# wl_phy_common_secure register map
Vendor: Texas Instruments
Peripheral module from a debugger description file (folder CC35X1E).
Registers are 32-bit, access per field, reset 0x0 unless marked. A register's access mark holds for its fields unless they carry their own. Offsets are as the file gives them; lines under a group give offsets from that group; [hi:lo] are bit positions; {n}, {i} and the like mark numbered series; 'fields as' and 'values as' point back to an identical list; <NAME> marks a mode.

## wl_phy_common_secure
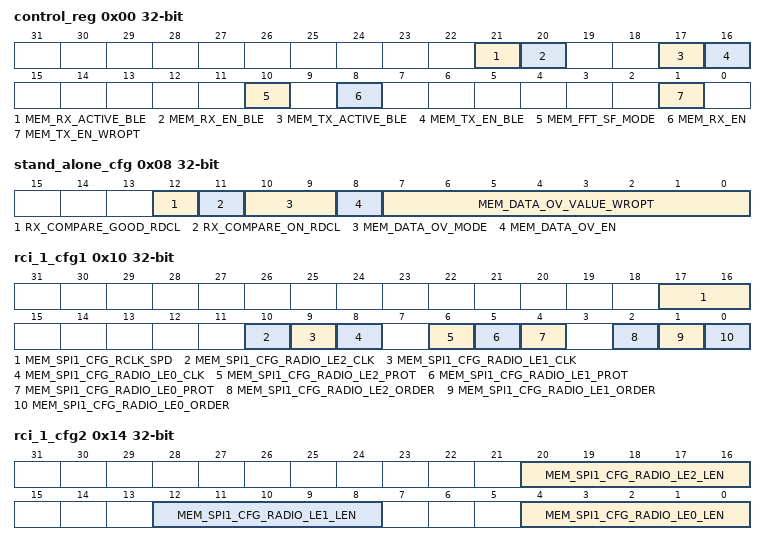
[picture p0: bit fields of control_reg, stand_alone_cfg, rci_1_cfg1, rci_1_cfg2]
0x00 control_reg reset not defined
  [21] MEM_RX_ACTIVE_BLE rw
  [20] MEM_RX_EN_BLE rw
  [17] MEM_TX_ACTIVE_BLE rw
  [16] MEM_TX_EN_BLE rw
  [10] MEM_FFT_SF_MODE rw
  [8] MEM_RX_EN rw — Rx En control 1 - En Rx 0 - Disable Rx
  [1] MEM_TX_EN_WROPT rw — Tx En control for clock Gating. Set by H/W upon MAC Header rise is detected by Tx Control module. Set by S/W to set tx clock and usually together with MEM_TX_START_WRCL. 1 - En Tx 0 - Disable Tx
0x04 fpga_ctrl reset not defined
  [13:0] MEM_FPGA_FC_INV rw
0x08 stand_alone_cfg
  [12] RX_COMPARE_GOOD_RDCL ro
  [11] RX_COMPARE_ON_RDCL ro
  [10:9] MEM_DATA_OV_MODE rw — 0 - Constant mode ('mem_data_ov_value' is transmitted) 1 - Increament mode ('mem_data_ov_value' is transmitted and increamented per tx_data_rd / rx_data_en) 2 - Memory mode ('mem_data_ov_3fc_wrmem' is transmitted one byte at a time starting from address 0)
  [8] MEM_DATA_OV_EN rw — 0 - Normal mode 1 - PHY srand alone mode - use data according to 'MEM_DATA_OV_MODE' instead of TX_DATA from MAC
  [7:0] MEM_DATA_OV_VALUE_WROPT rw — Use in Stand alone mode as: Tx - the TX_DATA Rx - the Compare date (when mem_data_ov_en=1)
0x0C fpga_spare1 rw
  [31:0] MEM_FPGA_SPARE1
0x10 rci_1_cfg1 reset not defined — Radio Serial Interface Configuration (RCI_CFG1)
  [17:16] MEM_SPI1_CFG_RCLK_SPD rw — Selects between 3 RCLK speeds depending on MAC clock frequency: 40/80 MHz MAC clock _ 0 = 6.67/13.33 MHz. 1 = 3.33/6.67 MHz. 2 or 3 = 1.67/3.33 MHz.
  [10] MEM_SPI1_CFG_RADIO_LE2_CLK rw — 1 - add an extra clock for the latch enable (to support the Nokia radio serial interface) for radio_le2.
  [9] MEM_SPI1_CFG_RADIO_LE1_CLK rw — 1 - add an extra clock for the latch enable (to support the Nokia radio serial interface) for radio_le1.
  [8] MEM_SPI1_CFG_RADIO_LE0_CLK rw — 1 - add an extra clock for the latch enable (to support the Nokia radio serial interface) for radio_le0.
  [6] MEM_SPI1_CFG_RADIO_LE2_PROT rw — Protocol for radio_le2 (0 = strobe. 1 = low active)
  [5] MEM_SPI1_CFG_RADIO_LE1_PROT rw — Protocol for radio_le1 (0 = strobe. 1 = low active) (Philips CS-SYNTH)
  [4] MEM_SPI1_CFG_RADIO_LE0_PROT rw — Protocol for radio_le0 (0 = strobe. 1 = low active) (Philips CS-1630)
  [2] MEM_SPI1_CFG_RADIO_LE2_ORDER rw — Bit order for radio_le2 (0 = lsb to msb. 1 = msb to lsb)
  [1] MEM_SPI1_CFG_RADIO_LE1_ORDER rw — Bit order for radio_le1 (0 = lsb to msb. 1 = msb to lsb) (Philips CS-SYNTH)
  [0] MEM_SPI1_CFG_RADIO_LE0_ORDER rw — Bit order for radio_le0 (0 = lsb to msb. 1 = msb to lsb) (Philips CS-1630)
0x14 rci_1_cfg2 reset not defined — Radio Serial Interface Register Length (RCI_CFG2)
  [20:16] MEM_SPI1_CFG_RADIO_LE2_LEN rw — The bit width of the internal radio registers for radio_le2
  [12:8] MEM_SPI1_CFG_RADIO_LE1_LEN rw — The bit width of the internal radio registers for radio_le1. (Philips CS-SYNTH)
  [4:0] MEM_SPI1_CFG_RADIO_LE0_LEN rw — The bit width of the internal radio registers for radio_le0. (Philips CS-1630)
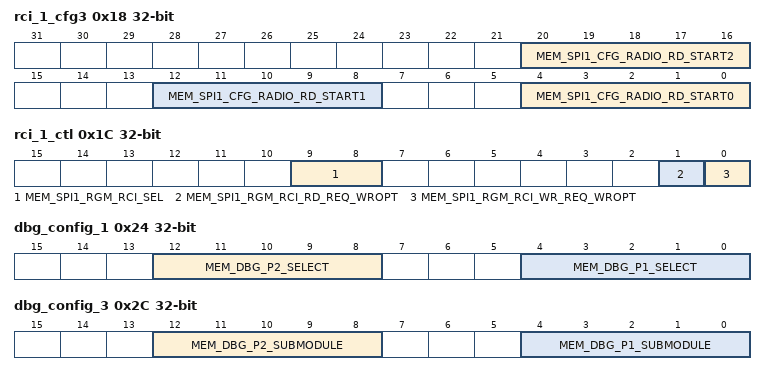
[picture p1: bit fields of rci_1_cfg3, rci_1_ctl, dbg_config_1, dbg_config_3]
0x18 rci_1_cfg3 — Radio Serial Interface Register Address Length (RCI_CFG3)
  [20:16] MEM_SPI1_CFG_RADIO_RD_START2 rw — For a register read, the number of bits to initially write, before reading the remaining bits for radio_le2.
  [12:8] MEM_SPI1_CFG_RADIO_RD_START1 rw — For a register read, the number of bits to initially write, before reading the remaining bits for radio_le1.
  [4:0] MEM_SPI1_CFG_RADIO_RD_START0 rw — For a register read, the number of bits to initially write, before reading the remaining bits for radio_le0.
0x1C rci_1_ctl — Radio Register Request (RCI_CTL)
  [9:8] MEM_SPI1_RGM_RCI_SEL rw — Select between latch enable 2. 1 or 0
  [1] MEM_SPI1_RGM_RCI_RD_REQ_WROPT rw — Read request. Cleared upon receiving ack strobe.
  [0] MEM_SPI1_RGM_RCI_WR_REQ_WROPT rw — Write request. Cleared upon receiving ack strobe.
0x20 rci_1_data rw — Radio Register Data (RCI_DATA)
  [31:0] MEM_SPI1_RGM_RCI_DATA_WROPT — Write data to radio registers
0x24 dbg_config_1
  [12:8] MEM_DBG_P2_SELECT rw, [4:0] MEM_DBG_P1_SELECT rw
0x2C dbg_config_3
  [12:8] MEM_DBG_P2_SUBMODULE rw, [4:0] MEM_DBG_P1_SUBMODULE rw
0x30 control_reg_2 reset not defined
  [0] MEM_TX_START_WRCL wo — Tx Start control When set to '1' will invoke Tx packet This field is self Clear (Clear on Write)
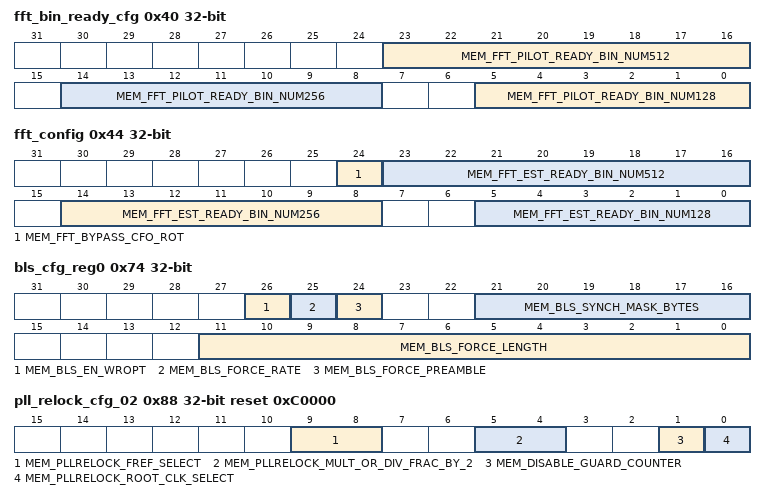
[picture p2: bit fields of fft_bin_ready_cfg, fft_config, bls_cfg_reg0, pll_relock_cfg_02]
0x40 fft_bin_ready_cfg reset not defined
  [23:16] MEM_FFT_PILOT_READY_BIN_NUM512 rw, [14:8] MEM_FFT_PILOT_READY_BIN_NUM256 rw, [5:0] MEM_FFT_PILOT_READY_BIN_NUM128 rw
0x44 fft_config reset not defined
  [24] MEM_FFT_BYPASS_CFO_ROT rw, [23:16] MEM_FFT_EST_READY_BIN_NUM512 rw, [14:8] MEM_FFT_EST_READY_BIN_NUM256 rw, [5:0] MEM_FFT_EST_READY_BIN_NUM128 rw
0x48 packet_cnt_bd_11b rw
  [31:0] MEM_PACKET_CNT_BD_11B_WROPT
0x4C packet_cnt_bd_ofdm rw
  [31:0] MEM_PACKET_CNT_BD_OFDM_WROPT
0x50 packet_cnt_rx_hdr rw
  [31:0] MEM_PACKET_CNT_RX_HDR_WROPT
0x54 packet_cnt_good_data rw
  [31:0] MEM_PACKET_CNT_GOOD_DATA_WROPT
0x58 packet_cnt_ls_reject rw
  [31:0] MEM_PACKET_CNT_LS_REJECT_WROPT
0x5C packet_cnt_stomp rw
  [31:0] MEM_PACKET_CNT_STOMP_WROPT
0x60 packet_cnt_rx_hdr_err rw
  [31:0] MEM_PACKET_CNT_RX_HDR_ERR_WROPT
0x64 packet_cnt_pd_dismissed rw
  [31:0] MEM_PACKET_CNT_PD_DISMISSED_WROPT
0x68 rf_balcony_sel_sw_reg ro
  [6:0] RF_BALCONY_SEL_SW — Read the Dip switch value Bit 0 -> SW8 (most right , near the Jtag Connector) Bit 5 -> SW2 (left side)
0x6C packet_cnt_tx_hdr rw
  [31:0] MEM_PACKET_CNT_TX_HDR_WROPT
0x70 packet_cnt_rx_unsupported rw
  [31:0] MEM_PACKET_CNT_RX_UNSUPPORTED_WROPT
0x74 bls_cfg_reg0 reset not defined
  [26] MEM_BLS_EN_WROPT rw — 0: Normal mode 1: BLS mode
  [25] MEM_BLS_FORCE_RATE rw — 0: 1DSSS 1: 2DSSS
  [24] MEM_BLS_FORCE_PREAMBLE rw — 0: Short Preamble 1: Long Preamble
  [21:16] MEM_BLS_SYNCH_MASK_BYTES rw — Mask the non-relevant bytes in the sequence
  [11:0] MEM_BLS_FORCE_LENGTH rw — The number of bytes to receive after sync
0x78 bls_cfg_reg1 rw
  [31:0] MEM_BLS_SYNCH_PATTERN_LSB — Synchronization pattern for BLS LSB bits [31:0]
0x7C bls_cfg_reg2
  [15:0] MEM_BLS_SYNCH_PATTERN_MSB rw — Synchronization pattern for BLS MSB bits [47:32]
0x80 pll_relock_cfg_00 — PLL Relock Configuration register
  [26:0] MEM_PLLRELOCK_CHANNEL_FREQ_MHZ rw — For Tx resampler ratio calculation <13.14u>
0x84 pll_relock_cfg_01 — PLL Relock Configuration register
  [0] MEM_PLLRELOCK_FW_TRIG_FOR_TXRESAMP_WRCL wo — Write clear - Using the divider of the Tx Resampler Ratio as HW accelerator for the FW
0x88 pll_relock_cfg_02 reset 0xC0000 (reset mask 0xFFFFFC00) — PLL Relock Configuration register
  [9:8] MEM_PLLRELOCK_FREF_SELECT rw — Selection of PLL reference clock: 0 - 80MHz 1 - 78MHz 2 - 104MHz 3 - 96MHz REF_CLK=(XTAL_CLK * DLL)/R
  [5:4] MEM_PLLRELOCK_MULT_OR_DIV_FRAC_BY_2 rw — Need to multiply or div by 2. 0 - mult by 1 1 - mult by 2 2 - div by 2 For 2.4GHz band = 0 or 1 For 5GHz band = 0 or 2
  [1] MEM_DISABLE_GUARD_COUNTER rw — This disable the guard of 7 clocks between calc done to going to IDLE. the reason is that we need to guarntee that two consecutive kicks are not asserted too fast. this could happen if trigger indication rise and then falls quickly. this counter make sure the kicks are spaced
  [0] MEM_PLLRELOCK_ROOT_CLK_SELECT rw — Selection of band == root clock: 0 - 2.4GHz band = 4/3 1 - 5GHz band = 4/7
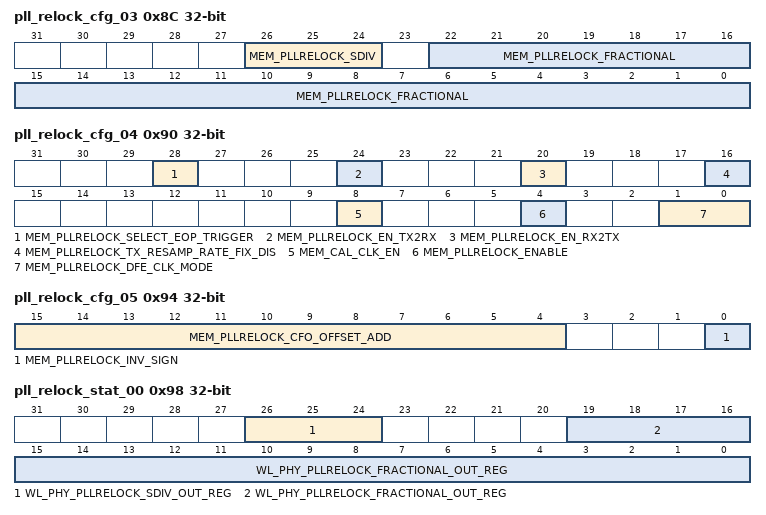
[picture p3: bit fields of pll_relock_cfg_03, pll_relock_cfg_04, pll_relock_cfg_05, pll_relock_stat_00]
0x8C pll_relock_cfg_03 — PLL Relock Configuration register
  [26:24] MEM_PLLRELOCK_SDIV rw — Original PLL sdiv word - will be written by PHY FW at tune
  [22:0] MEM_PLLRELOCK_FRACTIONAL rw — Fractional word - will be written by PHY FW at tune
0x90 pll_relock_cfg_04 reset not defined — PLL Relock Configuration register
  [28] MEM_PLLRELOCK_SELECT_EOP_TRIGGER rw — Select whether TdEop or TdDataEop triggers the PLL change 0 - TdEop 1 - TdDataEop
  [24] MEM_PLLRELOCK_EN_TX2RX rw — Enables actual PLL FCW change and Tx re-sampler update after the Tx of TB MU
  [20] MEM_PLLRELOCK_EN_RX2TX rw — Enables actual PLL FCW change and Tx re-sampler update once finish calculations, before Tx
  [16] MEM_PLLRELOCK_TX_RESAMP_RATE_FIX_DIS rw — Clibration clock enable
  [8] MEM_CAL_CLK_EN rw — Clibration clock enable
  [4] MEM_PLLRELOCK_ENABLE rw — Module Enabler
  [1:0] MEM_PLLRELOCK_DFE_CLK_MODE rw — Selection of Tx DFE clock mode, affects "Fin_div_Fout_ofdm_New" calculation 0 - BG (RCD32) 1 - A (CKVD48) 2 - E (CKVD64) 3 - BLE (RCD30)
0x94 pll_relock_cfg_05 — PLL Relock Configuration register
  [15:4] MEM_PLLRELOCK_CFO_OFFSET_ADD rw — An option to add external offset (i.e. temperature offset)
  [0] MEM_PLLRELOCK_INV_SIGN rw — In case Phase tracking output is inverted (Phase tracking output has similar configuration)
0x98 pll_relock_stat_00 ro — PLL Relock Status register
  [26:24] WL_PHY_PLLRELOCK_SDIV_OUT_REG — PLL sdiv calculated word - Status register to be used by FW as risk mitigation
  [19:0] WL_PHY_PLLRELOCK_FRACTIONAL_OUT_REG — PLL fractional calculated word - Status register to be used by FW as risk mitigation
0x9C pll_relock_stat_01 ro — PLL Relock Status register
  [25:0] WL_PHY_PLLRELOCK_TX_RESAMPLER_RATIO_OUT_REG — Tx re-sampler calculated word - Status register to be used by FW as risk mitigation
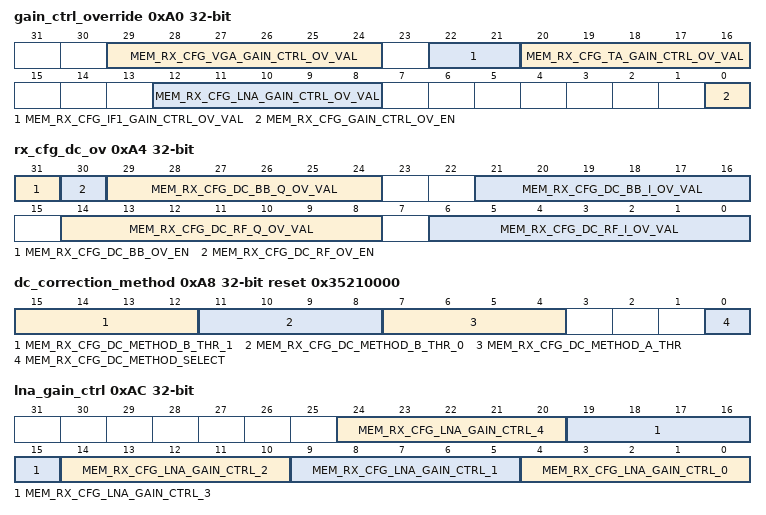
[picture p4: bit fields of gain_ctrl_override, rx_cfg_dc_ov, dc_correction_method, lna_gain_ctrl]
0xA0 gain_ctrl_override — RX CFG Gain Control Override configuration register
  [29:24] MEM_RX_CFG_VGA_GAIN_CTRL_OV_VAL rw — VGA override value (same for I&Q) <5.0>
  [22:21] MEM_RX_CFG_IF1_GAIN_CTRL_OV_VAL rw — IF1 override value (same for I&Q) <1.0>
  [20:16] MEM_RX_CFG_TA_GAIN_CTRL_OV_VAL rw — TA override value (same for I&Q) <4.0>
  [12:8] MEM_RX_CFG_LNA_GAIN_CTRL_OV_VAL rw — LNA override value <5.0>
  [0] MEM_RX_CFG_GAIN_CTRL_OV_EN rw — Override-enable. When this bit is set to '1', the amplifiers control will be according to OV_VAL registers
0xA4 rx_cfg_dc_ov — RX CFG DC Correction Override configuration register
  [31] MEM_RX_CFG_DC_BB_OV_EN rw — DC BB correction DAC override-enable. When this bit is set to '1', the DC BB DACs will get the OV_VAL
  [30] MEM_RX_CFG_DC_RF_OV_EN rw — DC RF correction DAC override-enable. When this bit is set to '1', the DC RF DACs will get the OV_VAL
  [29:24] MEM_RX_CFG_DC_BB_Q_OV_VAL rw — DC BB DAC Q correction word <5.0>
  [21:16] MEM_RX_CFG_DC_BB_I_OV_VAL rw — DC BB DAC I correction word <5.0>
  [14:8] MEM_RX_CFG_DC_RF_Q_OV_VAL rw — DC RF DAC Q correction word <8.0>
  [6:0] MEM_RX_CFG_DC_RF_I_OV_VAL rw — DC RF DAC I correction word <8.0>
0xA8 dc_correction_method reset 0x35210000 (reset mask 0xFFFF0000) — RX CFG DC Correction Method configuration register
  [15:12] MEM_RX_CFG_DC_METHOD_B_THR_1 rw — Method B only THR representing the maximum BB_index (maximum VGA gain [dB]) for using the calibrated BB correction divided by 4 <4.0>
  [11:8] MEM_RX_CFG_DC_METHOD_B_THR_0 rw — Method B only THR representing the minimum BB_index (minimum VGA gain [dB]) for using the calibrated BB correction <4.0>
  [7:4] MEM_RX_CFG_DC_METHOD_A_THR rw — Method A only THR representing the minimum BB_index (minimum VGA gain [dB]) for using the calibrated BB correction <4.0>
  [0] MEM_RX_CFG_DC_METHOD_SELECT rw — 0: Method A - BB Correction is valid up-to certain BB gain 1: Method B - "Considered" BB DAC correction
0xAC lna_gain_ctrl reset not defined — RX CFG LNA GAIN LUT configuration register A
  [5n+4:5n] MEM_RX_CFG_LNA_GAIN_CTRL_{n} rw (n=0..4) — LNA gain ctrl LUT {n} value
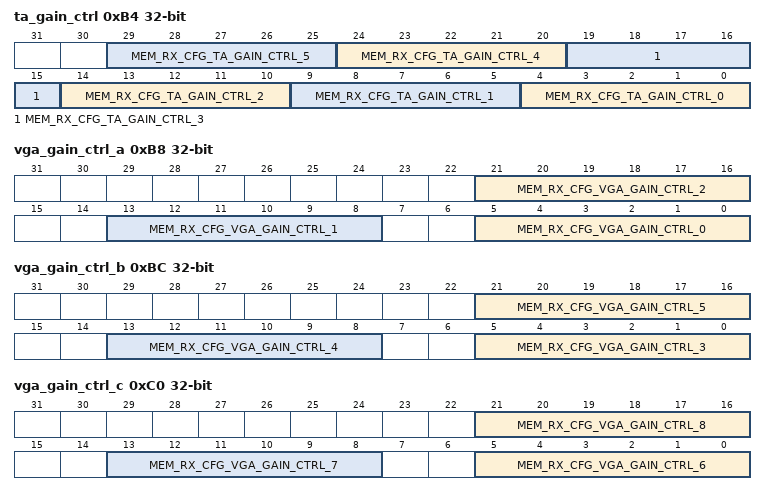
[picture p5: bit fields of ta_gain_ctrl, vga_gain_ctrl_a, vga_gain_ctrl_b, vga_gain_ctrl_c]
0xB4 ta_gain_ctrl reset not defined — RX CFG TA GAIN LUT configuration register
  [5n+4:5n] MEM_RX_CFG_TA_GAIN_CTRL_{n} rw (n=0..5) — TA gain ctrl LUT {n} value
0xB8 vga_gain_ctrl_a reset not defined — RX CFG VGA GAIN LUT configuration register A
  [21:16] MEM_RX_CFG_VGA_GAIN_CTRL_2 rw — VGA gain ctrl LUT 2 value
  [13:8] MEM_RX_CFG_VGA_GAIN_CTRL_1 rw — VGA gain ctrl LUT 1 value
  [5:0] MEM_RX_CFG_VGA_GAIN_CTRL_0 rw — VGA gain ctrl LUT 0 value
0xBC vga_gain_ctrl_b reset not defined — RX CFG VGA GAIN LUT configuration register B
  [21:16] MEM_RX_CFG_VGA_GAIN_CTRL_5 rw — VGA gain ctrl LUT 5 value
  [13:8] MEM_RX_CFG_VGA_GAIN_CTRL_4 rw — VGA gain ctrl LUT 4 value
  [5:0] MEM_RX_CFG_VGA_GAIN_CTRL_3 rw — VGA gain ctrl LUT 3 value
0xC0 vga_gain_ctrl_c reset not defined — RX CFG VGA GAIN LUT configuration register C
  [21:16] MEM_RX_CFG_VGA_GAIN_CTRL_8 rw — VGA gain ctrl LUT 8 value
  [13:8] MEM_RX_CFG_VGA_GAIN_CTRL_7 rw — VGA gain ctrl LUT 7 value
  [5:0] MEM_RX_CFG_VGA_GAIN_CTRL_6 rw — VGA gain ctrl LUT 6 value
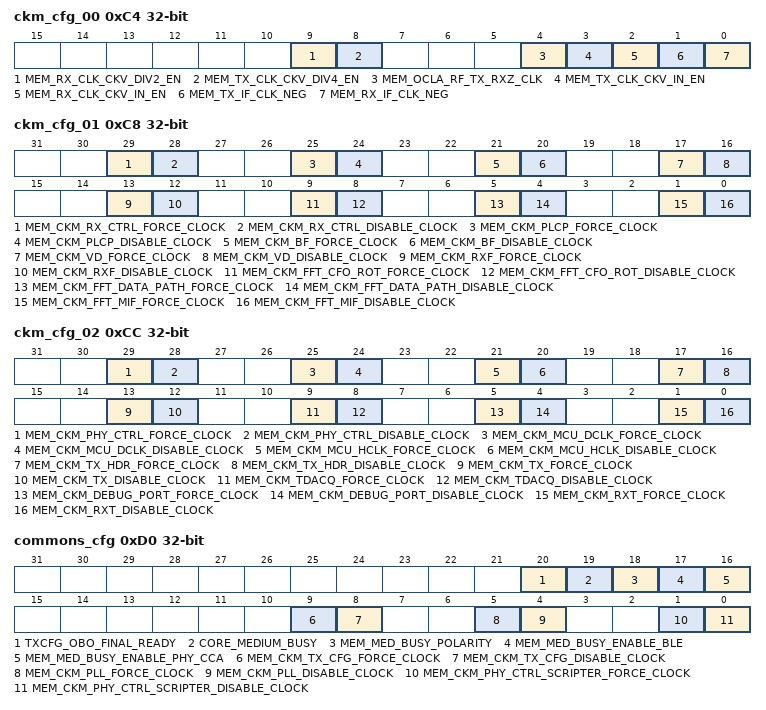
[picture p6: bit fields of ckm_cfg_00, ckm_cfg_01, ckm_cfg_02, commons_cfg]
0xC4 ckm_cfg_00 — CKM Configuration- CKV clock (Tx & Rx RF clocks)
  [9] MEM_RX_CLK_CKV_DIV2_EN rw, [8] MEM_TX_CLK_CKV_DIV4_EN rw, [4] MEM_OCLA_RF_TX_RXZ_CLK rw, [3] MEM_TX_CLK_CKV_IN_EN rw, [2] MEM_RX_CLK_CKV_IN_EN rw, [1] MEM_TX_IF_CLK_NEG rw, [0] MEM_RX_IF_CLK_NEG rw
0xC8 ckm_cfg_01
  [29] MEM_CKM_RX_CTRL_FORCE_CLOCK rw, [28] MEM_CKM_RX_CTRL_DISABLE_CLOCK rw, [25] MEM_CKM_PLCP_FORCE_CLOCK rw, [24] MEM_CKM_PLCP_DISABLE_CLOCK rw, [21] MEM_CKM_BF_FORCE_CLOCK rw, [20] MEM_CKM_BF_DISABLE_CLOCK rw, [17] MEM_CKM_VD_FORCE_CLOCK rw, [16] MEM_CKM_VD_DISABLE_CLOCK rw, [13] MEM_CKM_RXF_FORCE_CLOCK rw, [12] MEM_CKM_RXF_DISABLE_CLOCK rw, [9] MEM_CKM_FFT_CFO_ROT_FORCE_CLOCK rw, [8] MEM_CKM_FFT_CFO_ROT_DISABLE_CLOCK rw, [5] MEM_CKM_FFT_DATA_PATH_FORCE_CLOCK rw, [4] MEM_CKM_FFT_DATA_PATH_DISABLE_CLOCK rw, [1] MEM_CKM_FFT_MIF_FORCE_CLOCK rw, [0] MEM_CKM_FFT_MIF_DISABLE_CLOCK rw
0xCC ckm_cfg_02
  [29] MEM_CKM_PHY_CTRL_FORCE_CLOCK rw, [28] MEM_CKM_PHY_CTRL_DISABLE_CLOCK rw, [25] MEM_CKM_MCU_DCLK_FORCE_CLOCK rw, [24] MEM_CKM_MCU_DCLK_DISABLE_CLOCK rw, [21] MEM_CKM_MCU_HCLK_FORCE_CLOCK rw, [20] MEM_CKM_MCU_HCLK_DISABLE_CLOCK rw, [17] MEM_CKM_TX_HDR_FORCE_CLOCK rw, [16] MEM_CKM_TX_HDR_DISABLE_CLOCK rw, [13] MEM_CKM_TX_FORCE_CLOCK rw, [12] MEM_CKM_TX_DISABLE_CLOCK rw, [9] MEM_CKM_TDACQ_FORCE_CLOCK rw, [8] MEM_CKM_TDACQ_DISABLE_CLOCK rw, [5] MEM_CKM_DEBUG_PORT_FORCE_CLOCK rw, [4] MEM_CKM_DEBUG_PORT_DISABLE_CLOCK rw, [1] MEM_CKM_RXT_FORCE_CLOCK rw, [0] MEM_CKM_RXT_DISABLE_CLOCK rw
0xD0 commons_cfg
  [20] TXCFG_OBO_FINAL_READY ro — FInal OBO ready indication coming from TX CFG module
  [19] CORE_MEDIUM_BUSY ro — Current result of core medium busy as reflected to IO
  [18] MEM_MED_BUSY_POLARITY rw
  [17] MEM_MED_BUSY_ENABLE_BLE rw
  [16] MEM_MED_BUSY_ENABLE_PHY_CCA rw
  [9] MEM_CKM_TX_CFG_FORCE_CLOCK rw
  [8] MEM_CKM_TX_CFG_DISABLE_CLOCK rw
  [5] MEM_CKM_PLL_FORCE_CLOCK rw
  [4] MEM_CKM_PLL_DISABLE_CLOCK rw
  [1] MEM_CKM_PHY_CTRL_SCRIPTER_FORCE_CLOCK rw
  [0] MEM_CKM_PHY_CTRL_SCRIPTER_DISABLE_CLOCK rw
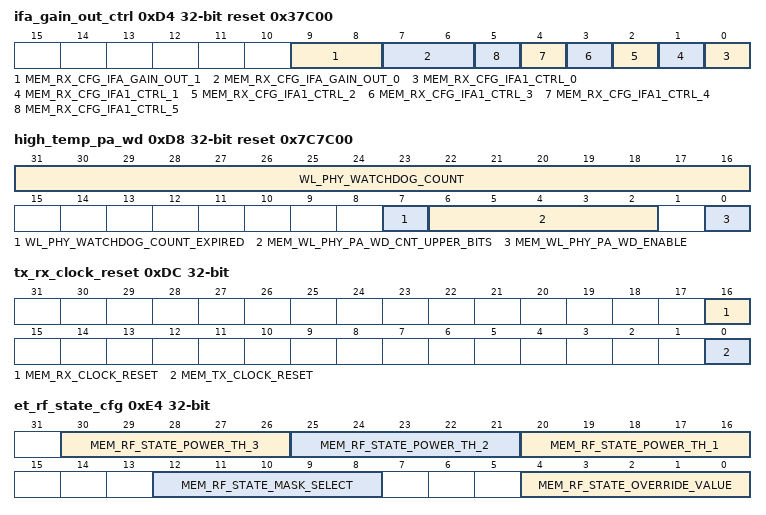
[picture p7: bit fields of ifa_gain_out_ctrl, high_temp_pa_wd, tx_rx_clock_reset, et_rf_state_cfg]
0xD4 ifa_gain_out_ctrl reset 0x37C00 (reset mask 0xFFFFFC00) — RX CFG IFA GAIN OUT LUT configuration register
  [9:8] MEM_RX_CFG_IFA_GAIN_OUT_1 rw — IFA gain out ctrl LUT 1 value
  [7:6] MEM_RX_CFG_IFA_GAIN_OUT_0 rw — IFA gain out ctrl LUT 0 value
  [n] MEM_RX_CFG_IFA1_CTRL_{n} rw (n=0..5) — IFA1 ctrl LUT {n} value
0xD8 high_temp_pa_wd reset 0x7C7C00 (reset mask 0xFFFFFF00) — This is a WD counter mechanism that has 16 bits counter while the upper 3 are configurable can be enabled/disabled FW needs to enable it on packet start should disable/clr the counter at packet end writing clr pulse start the counter from zero. the expired signal is shuting down the PA LDO
  [31:16] WL_PHY_WATCHDOG_COUNT ro, [7] WL_PHY_WATCHDOG_COUNT_EXPIRED ro, [6:2] MEM_WL_PHY_PA_WD_CNT_UPPER_BITS rw, [0] MEM_WL_PHY_PA_WD_ENABLE rw
0xDC tx_rx_clock_reset reset not defined
  [16] MEM_RX_CLOCK_RESET rw, [0] MEM_TX_CLOCK_RESET rw
0xE0 high_temp_pa_wd_02 — This is a WD counter mechanism that has 16 bits counter while the upper 3 are configurable can be enabled/disabled FW needs to enable it on packet start should disable/clr the counter at packet end writing clr pulse start the counter from zero. the expired signal is shuting down the PA LDO
  [0] MEM_WL_PHY_PA_CNT_START_WRCL wo
0xE4 et_rf_state_cfg reset not defined — Energy-Trace RF-State configuration
  [30:26] MEM_RF_STATE_POWER_TH_3 rw — POWER LEVEL Thteshold 3: Define: * Tx - Power Level3 MAX threshold * Tx - Power Level4 MIN threshold
  [25:21] MEM_RF_STATE_POWER_TH_2 rw — POWER LEVEL Thteshold 2: Define: * Tx - Power Level2 MAX threshold * Tx - Power Level3 MIN threshold
  [20:16] MEM_RF_STATE_POWER_TH_1 rw — POWER LEVEL Thteshold 1: Define: * Tx - Power Level1 MAX threshold * Tx - Power Level2 MIN threshold
  [12:8] MEM_RF_STATE_MASK_SELECT rw — A SELECT bit-wise option for the ET RF_STATE bits: Bit N - to seltct bit N - of ET RF_STATE_OVERRIDE
  [4:0] MEM_RF_STATE_OVERRIDE_VALUE rw — Value to override the ET RF_STATE according to MASK_SELECT bits
0x100 rx_cfg_dc_mem rw
  [31:0] MEM_RX_CFG_DC_124_WRMEM — RF_DAC_I - [ 7: 0] RF_DAC_Q - [15: 8] BB_DAC_I - [20:16] BB_DAC_Q - [28:24]
0x200 stand_alone_mem rw — An 128x8 memory that contains 128B for Tx stand alone transmission. When Tx stand Alone, 'mem_data_ov_en', is set and 'mem_data_ov_mode' is set to 0x2 ("Memory Mode"), this memory is transmitted one byte at a time starting from address 0
  [31:0] MEM_DATA_OV_2FC_WRMEMP
